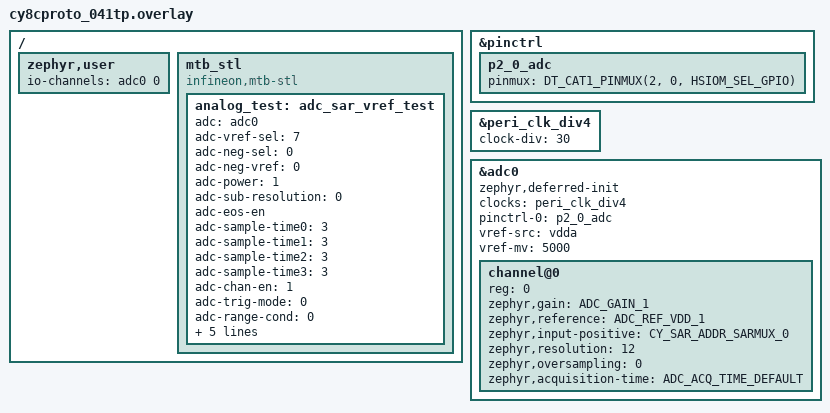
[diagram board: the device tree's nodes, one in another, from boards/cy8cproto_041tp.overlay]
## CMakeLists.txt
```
# SPDX-License-Identifier: Apache-2.0

cmake_minimum_required(VERSION 3.20.0)

find_package(Zephyr REQUIRED HINTS $ENV{ZEPHYR_BASE})
project(post_adc_stl_sample)

target_sources(app PRIVATE src/main.c)
```

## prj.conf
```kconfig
# POST subsystem
CONFIG_POST=y
CONFIG_POST_VENDOR_MTB_STL=y
CONFIG_POST_SHELL=y
CONFIG_POST_HALT_ON_FAILURE=n
CONFIG_POST_RUNTIME_TESTS=y

# Enable ADC MTB-STL tests
CONFIG_POST_MTB_STL_ANALOG=y

# Zephyr driver configs
CONFIG_ADC=y

# Shell support
CONFIG_SHELL=y

# Logging
CONFIG_LOG=y
CONFIG_POST_LOG_LEVEL=4
```

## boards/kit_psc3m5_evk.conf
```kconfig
# SPDX-FileCopyrightText: Copyright (c) 2026 Infineon Technologies AG,
# SPDX-FileCopyrightText: or an affiliate of Infineon Technologies AG. All rights reserved.
#
# SPDX-License-Identifier: Apache-2.0

CONFIG_DAC=y
```

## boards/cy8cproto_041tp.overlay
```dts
/*
 * Copyright (c) 2025 Infineon Technologies AG,
 * or an affiliate of Infineon Technologies AG.
 *
 * SPDX-License-Identifier: Apache-2.0
 */

#include <zephyr/dt-bindings/adc/adc.h>
#include <zephyr/dt-bindings/adc/infineon-sar.h>
#include <zephyr/dt-bindings/pinctrl/ifx_cat1-pinctrl.h>

&pinctrl {
	p2_0_adc: p2_0_adc {
		pinmux = <DT_CAT1_PINMUX(2, 0, HSIOM_SEL_GPIO)>;
	};
};

/* The clock initializes at boot: 48 MHz / 30 = 1.6 MHz for the SAR test. */
&peri_clk_div4 {
	status = "okay";
	clock-div = <30>;
};

&adc0 {
	status = "okay";
	/* Start the normal SAR driver only after PASS and cleanup. */
	zephyr,deferred-init;
	clocks = <&peri_clk_div4>;
	pinctrl-0 = <&p2_0_adc>;
	pinctrl-names = "default";
	vref-src = "vdda";
	vref-mv = <5000>;
	#address-cells = <1>;
	#size-cells = <0>;

	channel@0 {
		reg = <0>;
		zephyr,gain = "ADC_GAIN_1";
		zephyr,reference = "ADC_REF_VDD_1";
		zephyr,input-positive = <CY_SAR_ADDR_SARMUX_0>;
		zephyr,resolution = <12>;
		zephyr,oversampling = <0>;
		zephyr,acquisition-time = <ADC_ACQ_TIME_DEFAULT>;
	};
};

/ {
	zephyr,user {
		io-channels = <&adc0 0>;  /* Reference ADC0, channel 0 */
	};

	mtb_stl: mtb_stl {
		compatible = "infineon,mtb-stl";
		status = "okay";

		analog_test: adc_sar_vref_test{
			adc = <&adc0>;
			adc-vref-sel = <7>;
			adc-neg-sel = <0>;
			adc-neg-vref = <0>;
			adc-power = <1>;
			adc-sub-resolution = <0>;
			adc-eos-en;
			adc-sample-time0 = <3>;
			adc-sample-time1 = <3>;
			adc-sample-time2 = <3>;
			adc-sample-time3 = <3>;
			adc-chan-en = <1>;
			adc-trig-mode = <0>;
			adc-range-cond = <0>;
			adc-avg-cnt = <0>;
			adc-avg-shift;
			adc-sample-time-sel-ch = <0>;
			adc-sar-mux-switch-msk = <1>;
			adc-sar-mux-switch-hw-ctrl-msk = <1>;
		};
	};
};
```

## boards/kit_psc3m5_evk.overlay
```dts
/*
 * SPDX-FileCopyrightText: Copyright (c) 2026 Infineon Technologies AG,
 * SPDX-FileCopyrightText: or an affiliate of Infineon Technologies AG. All rights reserved.
 *
 * SPDX-License-Identifier: Apache-2.0
 */

#include <zephyr/dt-bindings/adc/adc.h>

&hppass_analog0 {
	trig-in-1-type = <3>;
};

&adc0 {
	status = "okay";
	ref-internal-source;
	#address-cells = <1>;
	#size-cells = <0>;

	channel@d {
		reg = <13>;
		zephyr,gain = "ADC_GAIN_1";
		zephyr,reference = "ADC_REF_INTERNAL";
		zephyr,acquisition-time = <ADC_ACQ_TIME_DEFAULT>;
		zephyr,resolution = <12>;
		zephyr,input-positive = <13>;
	};
};

/ {
	zephyr,user {
		io-channels = <&adc0 13>;
	};

	mtb_stl: mtb_stl {
		compatible = "infineon,mtb-stl";
		status = "okay";

		analog_test: adc_hppass_test {
			adc = <&adc0>;
			csg = <&csg0>;
			dac-slice = <0>;
		};
	};
};
```

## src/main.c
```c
/*
 * Copyright (c) 2026 Aerlync Labs Inc.
 * SPDX-License-Identifier: Apache-2.0
 */

#include <zephyr/kernel.h>
#include <zephyr/post/post.h>
#include <zephyr/shell/shell.h>
#include <zephyr/logging/log.h>

LOG_MODULE_REGISTER(post_adc_sample, LOG_LEVEL_INF);

int main(void)
{
	uint32_t passed;
	uint32_t failed;
	uint32_t skipped;

	printk("\n");
	printk("====================================\n");
	printk("Starting ADC POST sample application\n");
	printk("====================================\n");
	printk("\n");

	LOG_INF("POST subsystem initialized");
	LOG_INF("MTB-STL tests registered during boot");

	post_get_summary(&passed, &failed, &skipped);
	printk("POST summary: %u passed, %u failed, %u skipped\n", passed, failed, skipped);

	printk("Available shell commands:\n");
	printk("  post list   - List all registered POST tests\n");
	printk("  post run    - Run runtime POST tests\n");
	printk("  post status - Show POST test results\n");
	printk("\n");

	/* Application main loop */
	while (1) {
		k_sleep(K_SECONDS(5));
		LOG_DBG("Application running...");
	}

	return 0;
}
```
